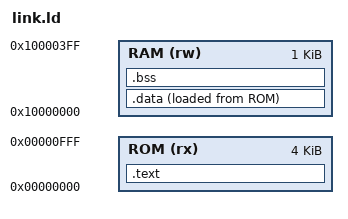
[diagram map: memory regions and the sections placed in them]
/* link.ld -- NavIC-SIPS: code and constants in boot ROM, state in data RAM */
MEMORY
{
    ROM (rx)  : ORIGIN = 0x00000000, LENGTH = 4K
    RAM (rw)  : ORIGIN = 0x10000000, LENGTH = 1K
}

ENTRY(_start)

SECTIONS
{
    .text : {
        KEEP(*(.text.start))
        *(.text .text.*)
        *(.rodata .rodata.* .srodata .srodata.*)
        . = ALIGN(4);
    } > ROM

    .data : {
        _data_start = .;
        *(.data .data.* .sdata .sdata.*)
        . = ALIGN(4);
        _data_end = .;
    } > RAM AT > ROM
    _data_load = LOADADDR(.data);

    .bss (NOLOAD) : {
        _bss_start = .;
        *(.bss .bss.* .sbss .sbss.* COMMON)
        . = ALIGN(4);
        _bss_end = .;
    } > RAM

    _stack_top = ORIGIN(RAM) + LENGTH(RAM);

    /DISCARD/ : { *(.comment) *(.riscv.attributes) }
}
